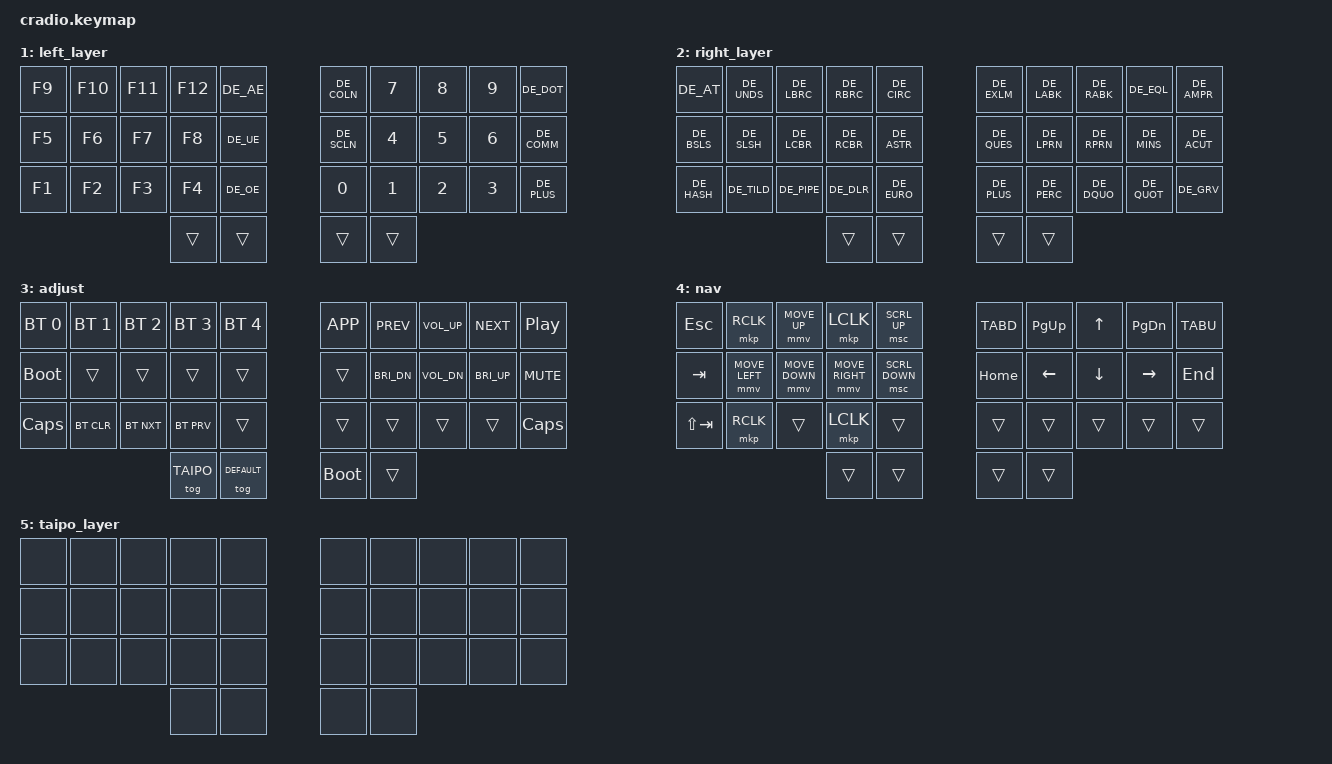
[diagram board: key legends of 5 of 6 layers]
// Copyright (c) 2022 The ZMK Contributors
// SPDX-License-Identifier: MIT

#include "german-keymap.h"
#include <behaviors.dtsi>
#include <dt-bindings/zmk/keys.h>
#include <dt-bindings/zmk/bt.h>
#include <dt-bindings/zmk/outputs.h>

#define HOST_OS 1  // set to 1 for Linux, default is 0 (Windows)
#include "../helpers/keymap-helpers.h"

/*#include "mouse.dtsi"*/

#include <dt-bindings/zmk/pointing.h>
#define ZMK_POINTING_DEFAULT_MOVE_VAL 1500  // 600
#define ZMK_POINTING_DEFAULT_SCRL_VAL 20    // 10

// Home row mods macro
#define HRML(k1,k2,k3,k4) &ht LGUI k1  &ht LALT k2  &ht LCTRL k3  &ht LSHFT k4
#define HRMR(k1,k2,k3,k4) &ht RSHFT k1  &ht RCTRL k2  &ht LALT k3  &ht RGUI k4

// layer names
#define DEFAULT 0
#define LOWER   1
#define RAISE   2
#define ADJUST  3
#define NAV     4
#define TAIPO   5

// custom keys
#define TABU LC(PG_DN)
#define TABD LC(PG_UP)

// taipo SETTINGS
#define TAPPING_TERM 200
#define COMBO_FAST_MS    30
#define COMBO_SLOW_MS    80
#define COMBO_GQT_MS     80

// CONFIG
#define COMBO_TIMEOUT 70
#define COMBO_LAYERS 5
#define STICKY_TIMEOUT 500

// LEFT SIDE
#define TLI 3 // TOP
#define TLM 2 // TOP
#define TLR 1 // TOP
#define TLP 0 // TOP
#define BLI 13 // BOTTOM
#define BLM 12 // BOTTOM
#define BLR 11 // BOTTOM
#define BLP 10 // BOTTOM
#define LOT 31 // O-THUMB
#define LIT 30 // I-THUMB

// RIGHT SIDE
#define TRI 6 // TOP
#define TRM 7 // TOP
#define TRR 8 // TOP
#define TRP 9 // TOP
#define BRI 16 // BOTTOM
#define BRM 17 // BOTTOM
#define BRR 18 // BOTTOM
#define BRP 19 // BOTTOM
#define ROT 32 // O-THUMB
#define RIT 33 // I-THUMB

&lt { quick_tap_ms = <200>; };

/ {
    behaviors {
        ht: hold_tap {
            compatible = "zmk,behavior-hold-tap";
            #binding-cells = <2>;
            /*flavor = "tap-preferred";*/
            flavor = "balanced";
            tapping-term-ms = <200>;
            quick-tap-ms = <0>;
            /*global-quick-tap;*/
            bindings = <&kp>, <&kp>;
        };
    };

    combos {
        compatible = "zmk,combos";
        combo_ss {
            timeout-ms = <50>;
            key-positions = <12 27>;
            bindings = <&kp DE_SS>;
        };
        // combo_adj_l {
        //     timeout-ms = <50>;
        //     key-positions = <22 23>;
        //     bindings = <&mo LOWER>;
        //     layers = <0 TAIPO>;
        // };
        // combo_adj_r {
        //     timeout-ms = <50>;
        //     key-positions = <26 27>;
        //     bindings = <&mo RAISE>;
        //     layers = <0 TAIPO>;
        // };
        #include "taipo.dtsi" // taipo combos only available in layer 5
    };

    conditional_layers {
        compatible = "zmk,conditional-layers";
        tri_layer {
            if-layers = <LOWER RAISE>;
            then-layer = <ADJUST>;
        };
    };

    keymap {
        compatible = "zmk,keymap";
        default_layer {
            bindings = <
        //╭──────────┬──────────┬──────────┬──────────┬──────────╮   ╭──────────┬──────────┬──────────┬──────────┬──────────╮
        //│  Q       │  W       │  F       │  P       │  B       │   │  J       │  L       │  U       │ Y        │  P       │
            &kp DE_Q  &kp DE_W      &kp DE_F      &kp DE_P      &kp DE_B          &kp DE_J      &kp DE_L      &kp DE_U      &kp DE_Y      &kp DE_PLUS
        //├──────────┼──────────┼──────────┼──────────┼──────────┤   ├──────────┼──────────┼──────────┼──────────┼──────────┤
        //│  A       │  S       │  D       │  F       │  G       │   │  H       │  J       │  K       │  L       │ ' "      │
            HRML(DE_A, DE_R,         DE_S,         DE_T)     &kp DE_G          &kp DE_M      HRMR(DE_N,        DE_E,         DE_I,        DE_O)
        //├──────────┼──────────┼──────────┼──────────┼──────────┤   ├──────────┼──────────┼──────────┼──────────┼──────────┤
        //│  Z       │  X       │  C       │  V       │  B       │   │  N       │  M       │ , <      │ . >      │ / ?      │
            &kp DE_Z  &kp DE_X      &kp DE_C      &kp DE_D      &kp DE_V          &kp DE_K      &kp DE_H      &kp DE_COMM  &kp DE_DOT    &kp DE_MINS
        //╰──────────┴──────────┴──────────┼──────────┼──────────┤   ├──────────┼──────────┼──────────┴──────────┴──────────╯
                                         &lt LOWER DEL  &lt NAV SPC    &kp BSPC   &lt RAISE RET
        //                                 ╰──────────┴──────────╯   ╰──────────┴──────────╯
            >;
        };

        left_layer {
            bindings = <
        //╭──────────┬──────────┬──────────┬──────────┬──────────╮   ╭──────────┬──────────┬──────────┬──────────┬──────────╮
        //│          │  [       │  {       │  }       │          │   │  ^       │  (       │  )       │  ]       │  ~       │
           &kp F9     &kp F10    &kp F11    &kp F12    &kp DE_AE      &kp DE_COLN  &kp N7  &kp N8  &kp N9  &kp DE_DOT
        //├──────────┼──────────┼──────────┼──────────┼──────────┤   ├──────────┼──────────┼──────────┼──────────┼──────────┤
        //│  !       │  @       │  #       │  $       │  %       │   │  *       │  -       │  =       │  \       │  `       │
            &kp F5    &kp F6     &kp F7     &kp F8     &kp DE_UE      &kp DE_SCLN  &kp N4  &kp N5  &kp N6  &kp DE_COMM
        //├──────────┼──────────┼──────────┼──────────┼──────────┤   ├──────────┼──────────┼──────────┼──────────┼──────────┤
        //│          │          │          │          │          │   │  &       │  _       │  +       │  │       │          │
            &kp F1    &kp F2     &kp F3     &kp F4     &kp DE_OE      &kp N0     &kp N1  &kp N2  &kp N3  &kp DE_PLUS
        //╰──────────┴──────────┴──────────┼──────────┼──────────┤   ├──────────┼──────────┼──────────┴──────────┴──────────╯
                                            &trans     &trans         &trans     &trans
        //                                 ╰──────────┴──────────╯   ╰──────────┴──────────╯
            >;
        };

        right_layer {
            bindings = <
        //╭──────────┬──────────┬──────────┬──────────┬──────────╮   ╭──────────┬──────────┬──────────┬──────────┬──────────╮
        //│ INSERT   │  1       │  2       │  3       │          │   │ HOME     │ PAGE DN  │ PAGE UP  │ END      │  :       │
            &kp DE_AT &kp DE_UNDS  &kp DE_LBRC    &kp DE_RBRC   &kp DE_CIRC      &kp DE_EXLM   &kp DE_LABK     &kp DE_RABK     &kp DE_EQL  &kp DE_AMPR
        //├──────────┼──────────┼──────────┼──────────┼──────────┤   ├──────────┼──────────┼──────────┼──────────┼──────────┤
        //│ DELETE   │  4       │  5       │  6       │          │   │ LEFT     │ DOWN     │ UP       │ RIGHT    │  ;       │
            &kp DE_BSLS  &kp DE_SLSH   &kp DE_LCBR   &kp DE_RCBR   &kp DE_ASTR       &kp DE_QUES  &kp DE_LPRN   &kp DE_RPRN   &kp DE_MINS  &kp DE_ACUT
        //├──────────┼──────────┼──────────┼──────────┼──────────┤   ├──────────┼──────────┼──────────┼──────────┼──────────┤
        //│ CAPS     │  7       │  8       │  9       │  0       │   │          │          │          │          │          │
           &kp DE_HASH   &kp DE_TILD  &kp DE_PIPE   &kp DE_DLR &kp DE_EURO       &kp DE_PLUS   &kp DE_PERC  &kp DE_DQUO    &kp DE_QUOT    &kp DE_GRV
        //╰──────────┴──────────┴──────────┼──────────┼──────────┤   ├──────────┼──────────┼──────────┴──────────┴──────────╯
                                            &trans     &trans         &trans     &trans
        //                                 ╰──────────┴──────────╯   ╰──────────┴──────────╯
            >;
        };


        adjust {
            bindings = <
        //╭──────────┬──────────┬──────────┬──────────┬──────────╮        ╭──────────┬────────────┬────────────┬────────────┬──────────╮
        //│          │          │          │          │          │        │          │            │            │            │  RESET   │
        &bt BT_SEL 0  &bt BT_SEL 1 &bt BT_SEL 2 &bt BT_SEL 3 &bt BT_SEL 4  &kp K_APP  &kp C_PREV   &kp C_VOL_UP &kp C_NEXT   &kp C_PP
        //├──────────┼──────────┼──────────┼──────────┼──────────┤        ├──────────┼────────────┼────────────┼────────────┼──────────┤
        //│BOOTLOADER│          │          │          │          │        │          │            │            │            │BOOTLOADER│
          &bootloader &trans       &trans       &trans       &trans        &trans     &kp C_BRI_DN &kp C_VOL_DN &kp C_BRI_UP &kp C_MUTE
        //├──────────┼──────────┼──────────┼──────────┼──────────┤        ├──────────┼────────────┼────────────┼────────────┼──────────┤
        //│          │          │          │          │          │        │          │            │            │            │          │
           &kp CAPS   &bt BT_CLR   &bt BT_NXT   &bt BT_PRV   &trans        &trans     &trans       &trans       &trans       &kp CAPS
        //╰──────────┴──────────┴──────────┼──────────┼──────────┤        ├──────────┼────────────┼────────────┴────────────┴──────────╯
                                             &tog TAIPO    &tog DEFAULT    &bootloader &trans
        //                                 ╰──────────┴──────────╯        ╰──────────┴──────────╯
            >;
        };

        /*nav {*/
        /*    bindings = <*/
        /*//╭──────────┬──────────┬──────────┬──────────┬──────────╮   ╭─────────────┬──────────┬──────────┬──────────┬─────────────╮*/
        /*   &kp ESC    &mkp RCLK      U_MS_U     U_BTN1     U_WH_U     &kp TABD      &kp PG_UP  &kp UP     &kp PG_DN  &kp TABU*/
        /*//├──────────┼──────────┼──────────┼──────────┼──────────┤   ├─────────────┼──────────┼──────────┼──────────┼─────────────┤*/
        /*   &kp TAB        U_MS_L     U_MS_D     U_MS_R     U_WH_U     &kp HOME      &kp LEFT   &kp DOWN   &kp RIGHT  &kp END*/
        /*//├──────────┼──────────┼──────────┼──────────┼──────────┤   ├─────────────┼──────────┼──────────┼──────────┼─────────────┤*/
        /*  &kp LS(TAB)     U_BTN2     U_BTN3     U_BTN1 &trans         &trans        &trans     &trans     &trans     &trans*/
        /*//╰──────────┴──────────┴──────────┼──────────┼──────────┤   ├─────────────┼──────────┼──────────┴──────────┴─────────────╯*/
        /*                                     &trans     &trans         &trans       &trans*/
        /*//                                 ╰──────────┴──────────╯   ╰─────────────┴──────────╯*/
        /*    >;*/
        /*};*/
        nav {
            bindings = <
        //╭──────────┬──────────    ┬─────────      ┬──────────┬        ──────────╮   ╭─────────────┬──────────┬──────────┬──────────┬─────────────╮
           &kp ESC    &mkp RCLK      &mmv MOVE_UP    &mkp LCLK       &msc SCRL_UP      &kp TABD      &kp PG_UP  &kp UP     &kp PG_DN  &kp TABU
        //├──────────┼──────────    ┼──────────     ┼──────────     ┼──────────┤      ├─────────────┼──────────┼──────────┼──────────┼─────────────┤
           &kp TAB    &mmv MOVE_LEFT &mmv MOVE_DOWN  &mmv MOVE_RIGHT &msc SCRL_DOWN    &kp HOME      &kp LEFT   &kp DOWN   &kp RIGHT  &kp END
        //├──────────┼─────────    ─┼─────────     ─┼  ───────     ─┼──────────┤      ├─────────────┼──────────┼──────────┼──────────┼─────────────┤
          &kp LS(TAB) &mkp RCLK      &trans          &mkp LCLK       &trans            &trans        &trans     &trans     &trans     &trans
        //╰──────────┴─────────    ─┴─────────     ─┼  ─────────   ─┼──────────┤      ├─────────────┼──────────┼──────────┴──────────┴─────────────╯
                                                     &trans          &trans            &trans       &trans
        //                                          ╰─────────     ─┴──────────╯      ╰─────────────┴──────────╯
            >;
        };
        taipo_layer {
          bindings = <
            &none           &none            &none             &none            &none                 &none            &none            &none            &none            &none
            &none           &none            &none             &none            &none                 &none            &none            &none            &none            &none
            &none           &none            &none             &none            &none                 &none            &none            &none            &none            &none
                                                               &none            &none                 &none            &none
          >;
        };
    };
};

/* vim: set ft=cpp tw=174: */
